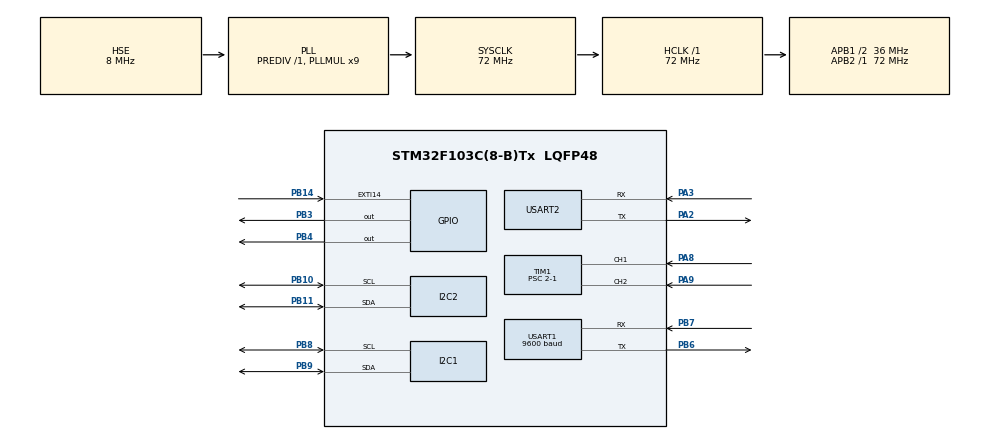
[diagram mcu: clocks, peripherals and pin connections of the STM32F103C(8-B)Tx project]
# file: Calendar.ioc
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Dma.I2C2_RX.3.Direction=DMA_PERIPH_TO_MEMORY
Dma.I2C2_RX.3.Instance=DMA1_Channel5
Dma.I2C2_RX.3.MemDataAlignment=DMA_MDATAALIGN_BYTE
Dma.I2C2_RX.3.MemInc=DMA_MINC_ENABLE
Dma.I2C2_RX.3.Mode=DMA_NORMAL
Dma.I2C2_RX.3.PeriphDataAlignment=DMA_PDATAALIGN_BYTE
Dma.I2C2_RX.3.PeriphInc=DMA_PINC_DISABLE
Dma.I2C2_RX.3.Priority=DMA_PRIORITY_LOW
Dma.I2C2_TX.2.Direction=DMA_MEMORY_TO_PERIPH
Dma.I2C2_TX.2.Instance=DMA1_Channel4
Dma.I2C2_TX.2.MemDataAlignment=DMA_MDATAALIGN_BYTE
Dma.I2C2_TX.2.MemInc=DMA_MINC_ENABLE
Dma.I2C2_TX.2.Mode=DMA_NORMAL
Dma.I2C2_TX.2.PeriphDataAlignment=DMA_PDATAALIGN_BYTE
Dma.I2C2_TX.2.PeriphInc=DMA_PINC_DISABLE
Dma.I2C2_TX.2.Priority=DMA_PRIORITY_LOW
Dma.Request0=USART2_RX
Dma.Request1=USART2_TX
Dma.Request2=I2C2_TX
Dma.Request3=I2C2_RX
Dma.USART2_RX.0.Direction=DMA_PERIPH_TO_MEMORY
Dma.USART2_RX.0.Instance=DMA1_Channel6
Dma.USART2_RX.0.MemDataAlignment=DMA_MDATAALIGN_BYTE
Dma.USART2_RX.0.MemInc=DMA_MINC_ENABLE
Dma.USART2_RX.0.Mode=DMA_NORMAL
Dma.USART2_RX.0.PeriphDataAlignment=DMA_PDATAALIGN_BYTE
Dma.USART2_RX.0.PeriphInc=DMA_PINC_DISABLE
Dma.USART2_RX.0.Priority=DMA_PRIORITY_LOW
Dma.USART2_TX.1.Direction=DMA_MEMORY_TO_PERIPH
Dma.USART2_TX.1.Instance=DMA1_Channel7
Dma.USART2_TX.1.MemDataAlignment=DMA_MDATAALIGN_BYTE
Dma.USART2_TX.1.MemInc=DMA_MINC_ENABLE
Dma.USART2_TX.1.Mode=DMA_NORMAL
Dma.USART2_TX.1.PeriphDataAlignment=DMA_PDATAALIGN_BYTE
Dma.USART2_TX.1.PeriphInc=DMA_PINC_DISABLE
Dma.USART2_TX.1.Priority=DMA_PRIORITY_LOW
I2C1.I2C_Mode=I2C_Fast
Mcu.Family=STM32F1
Mcu.Name=STM32F103C(8-B)Tx
Mcu.Package=LQFP48
NVIC.DMA1_Channel4_IRQn=true\:0\:0\:false\:false\:true\:false\:true\:true
NVIC.DMA1_Channel5_IRQn=true\:0\:0\:false\:false\:true\:false\:true\:true
NVIC.DMA1_Channel6_IRQn=true\:0\:0\:false\:false\:true\:false\:true\:true
NVIC.DMA1_Channel7_IRQn=true\:0\:0\:false\:false\:true\:false\:true\:true
NVIC.EXTI15_10_IRQn=true\:0\:0\:false\:false\:true\:true\:true\:true
NVIC.I2C2_ER_IRQn=true\:0\:0\:false\:false\:true\:true\:true\:true
NVIC.I2C2_EV_IRQn=true\:0\:0\:false\:false\:true\:true\:true\:true
NVIC.PriorityGroup=NVIC_PRIORITYGROUP_4
NVIC.USART1_IRQn=true\:0\:0\:false\:false\:true\:true\:true\:true
NVIC.USART2_IRQn=true\:0\:0\:false\:false\:true\:true\:true\:true
PA13.Mode=Serial_Wire
PA13.Signal=SYS_JTMS-SWDIO
PA14.Mode=Serial_Wire
PA14.Signal=SYS_JTCK-SWCLK
PA2.Mode=Asynchronous
PA2.Signal=USART2_TX
PA3.Mode=Asynchronous
PA3.Signal=USART2_RX
PA8.Signal=S_TIM1_CH1
PA9.Signal=S_TIM1_CH2
PB10.Mode=I2C
PB10.Signal=I2C2_SCL
PB11.Mode=I2C
PB11.Signal=I2C2_SDA
PB14.GPIO_ModeDefaultEXTI=GPIO_MODE_IT_FALLING
PB14.GPIO_PuPd=GPIO_PULLUP
PB14.Signal=GPXTI14
PB3.GPIO_PuPd=GPIO_PULLDOWN
PB3.PinState=GPIO_PIN_RESET
PB3.Signal=GPIO_Output
PB4.GPIO_PuPd=GPIO_PULLDOWN
PB4.Signal=GPIO_Output
PB6.Mode=Asynchronous
PB6.Signal=USART1_TX
PB7.Mode=Asynchronous
PB7.Signal=USART1_RX
PB8.Mode=I2C
PB8.Signal=I2C1_SCL
PB9.Mode=I2C
PB9.Signal=I2C1_SDA
PC14-OSC32_IN.Mode=LSE-External-Oscillator
PC14-OSC32_IN.Signal=RCC_OSC32_IN
PC15-OSC32_OUT.Mode=LSE-External-Oscillator
PC15-OSC32_OUT.Signal=RCC_OSC32_OUT
PD0-OSC_IN.Mode=HSE-External-Oscillator
PD0-OSC_IN.Signal=RCC_OSC_IN
PD1-OSC_OUT.Mode=HSE-External-Oscillator
PD1-OSC_OUT.Signal=RCC_OSC_OUT
ProjectManager.HeapSize=0x200
ProjectManager.StackSize=0x400
ProjectManager.TargetToolchain=MDK-ARM V5.32
RCC.AHBFreq_Value=72000000
RCC.APB1CLKDivider=RCC_HCLK_DIV2
RCC.APB1Freq_Value=36000000
RCC.APB1TimFreq_Value=72000000
RCC.APB2Freq_Value=72000000
RCC.APB2TimFreq_Value=72000000
RCC.HCLKFreq_Value=72000000
RCC.PLLMUL=RCC_PLL_MUL9
RCC.PLLSourceVirtual=RCC_PLLSOURCE_HSE
RCC.SYSCLKFreq_VALUE=72000000
RCC.SYSCLKSource=RCC_SYSCLKSOURCE_PLLCLK
RCC.USBFreq_Value=72000000
SH.S_TIM1_CH1.0=TIM1_CH1,Encoder_Interface
SH.S_TIM1_CH2.0=TIM1_CH2,Encoder_Interface
TIM1.IC1Filter=15
TIM1.IC1Polarity=TIM_ICPOLARITY_RISING
TIM1.IC2Filter=15
TIM1.Prescaler=2-1
TIM4.Prescaler=72-1
USART1.BaudRate=9600
USART1.VirtualMode=VM_ASYNC
USART2.VirtualMode=VM_ASYNC
VP_RTC_VS_RTC_Activate.Mode=RTC_Enabled
VP_TIM4_VS_ClockSourceINT.Mode=Internal
board=custom

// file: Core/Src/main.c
/* USER CODE BEGIN Header */
/**
  ******************************************************************************
  * @file           : main.c
  * @brief          : Main program body
  ******************************************************************************
  * @attention
  *
  * Copyright (c) 2026 STMicroelectronics.
  * All rights reserved.
  *
  * This software is licensed under terms that can be found in the LICENSE file
  * in the root directory of this software component.
  * If no LICENSE file comes with this software, it is provided AS-IS.
  *
  ******************************************************************************
  */
/* USER CODE END Header */
#include "main.h"
#include "dma.h"
#include "i2c.h"
#include "rtc.h"
#include "tim.h"
#include "usart.h"
#include "gpio.h"

/* USER CODE BEGIN Includes */
#include "oled.h"
#include "main_task.h"
#include "font.h"
#include "RTC_Tesk.h"
#include "stdio.h"
#include "string.h"
#include "ATH20.h"
/* USER CODE END Includes */

void SystemClock_Config(void);

int main(void)
{

  /* MCU Configuration--------------------------------------------------------*/

  /* Reset of all peripherals, Initializes the Flash interface and the Systick. */
  HAL_Init();

  /* Configure the system clock */
  SystemClock_Config();

  /* Initialize all configured peripherals */
  MX_GPIO_Init();
  MX_DMA_Init();
  MX_I2C1_Init();
  MX_USART2_UART_Init();
  MX_RTC_Init();
  MX_TIM1_Init();
  MX_I2C2_Init();
  MX_USART1_UART_Init();
  MX_TIM4_Init();
  /* USER CODE BEGIN 2 */
  __HAL_RCC_AFIO_CLK_ENABLE();
  __HAL_AFIO_REMAP_SWJ_NOJTAG();
  MainTaskInit();

  /* USER CODE END 2 */

  /* Infinite loop */
  /* USER CODE BEGIN WHILE */
  while (1)
  {

    MainTask();
  }
}

void SystemClock_Config(void)
{
  RCC_OscInitTypeDef RCC_OscInitStruct = {0};
  RCC_ClkInitTypeDef RCC_ClkInitStruct = {0};
  RCC_PeriphCLKInitTypeDef PeriphClkInit = {0};

  /** Initializes the RCC Oscillators according to the specified parameters
  * in the RCC_OscInitTypeDef structure.
  */
  RCC_OscInitStruct.OscillatorType = RCC_OSCILLATORTYPE_LSI|RCC_OSCILLATORTYPE_HSE;
  RCC_OscInitStruct.HSEState = RCC_HSE_ON;
  RCC_OscInitStruct.HSEPredivValue = RCC_HSE_PREDIV_DIV1;
  RCC_OscInitStruct.HSIState = RCC_HSI_ON;
  RCC_OscInitStruct.LSIState = RCC_LSI_ON;
  RCC_OscInitStruct.PLL.PLLState = RCC_PLL_ON;
  RCC_OscInitStruct.PLL.PLLSource = RCC_PLLSOURCE_HSE;
  RCC_OscInitStruct.PLL.PLLMUL = RCC_PLL_MUL9;
  if (HAL_RCC_OscConfig(&RCC_OscInitStruct) != HAL_OK)
  {
    Error_Handler();
  }

  /** Initializes the CPU, AHB and APB buses clocks
  */
  RCC_ClkInitStruct.ClockType = RCC_CLOCKTYPE_HCLK|RCC_CLOCKTYPE_SYSCLK
                              |RCC_CLOCKTYPE_PCLK1|RCC_CLOCKTYPE_PCLK2;
  RCC_ClkInitStruct.SYSCLKSource = RCC_SYSCLKSOURCE_PLLCLK;
  RCC_ClkInitStruct.AHBCLKDivider = RCC_SYSCLK_DIV1;
  RCC_ClkInitStruct.APB1CLKDivider = RCC_HCLK_DIV2;
  RCC_ClkInitStruct.APB2CLKDivider = RCC_HCLK_DIV1;

  if (HAL_RCC_ClockConfig(&RCC_ClkInitStruct, FLASH_LATENCY_2) != HAL_OK)
  {
    Error_Handler();
  }
  PeriphClkInit.PeriphClockSelection = RCC_PERIPHCLK_RTC;
  PeriphClkInit.RTCClockSelection = RCC_RTCCLKSOURCE_LSI;
  if (HAL_RCCEx_PeriphCLKConfig(&PeriphClkInit) != HAL_OK)
  {
    Error_Handler();
  }
}

void Error_Handler(void)
{
  __disable_irq();
  while (1)
  {
  }
}
